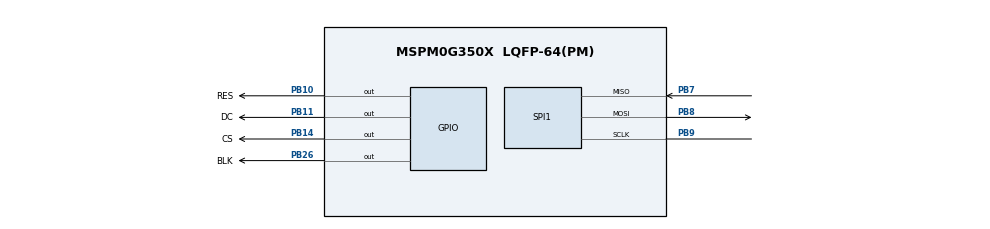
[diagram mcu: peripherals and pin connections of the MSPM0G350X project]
/**
 * @cliArgs --device "MSPM0G350X" --part "Default" --package "LQFP-64(PM)" --product "mspm0_sdk@2.10.00.04"
 * @versions {"tool":"1.26.2+4477"}
 */

/**
 * Import the modules used in this configuration.
 */
const GPIO   = scripting.addModule("/ti/driverlib/GPIO", {}, false);
const GPIO1  = GPIO.addInstance();
const SPI    = scripting.addModule("/ti/driverlib/SPI", {}, false);
const SPI1   = SPI.addInstance();
const SYSCTL = scripting.addModule("/ti/driverlib/SYSCTL");

/**
 * Write custom configuration values to the imported modules.
 */
GPIO1.port                          = "PORTB";
GPIO1.$name                         = "LCD";
GPIO1.associatedPins.create(4);
GPIO1.associatedPins[0].$name       = "RES";
GPIO1.associatedPins[0].ioStructure = "SD";
GPIO1.associatedPins[0].pin.$assign = "PB10";
GPIO1.associatedPins[1].$name       = "DC";
GPIO1.associatedPins[1].ioStructure = "SD";
GPIO1.associatedPins[1].pin.$assign = "PB11";
GPIO1.associatedPins[2].$name       = "CS";
GPIO1.associatedPins[2].ioStructure = "SD";
GPIO1.associatedPins[2].pin.$assign = "PB14";
GPIO1.associatedPins[3].$name       = "BLK";
GPIO1.associatedPins[3].ioStructure = "SD";
GPIO1.associatedPins[3].pin.$assign = "PB26";

const Board = scripting.addModule("/ti/driverlib/Board", {}, false);

SPI1.$name                              = "SPI_LCD";
SPI1.frameFormat                        = "MOTO3";
SPI1.targetBitRate                      = 2000000;
SPI1.sclkPinConfig.$name                = "ti_driverlib_gpio_GPIOPinGeneric0";
SPI1.sclkPinConfig.direction            = scripting.forceWrite("OUTPUT");
SPI1.sclkPinConfig.onlyInternalResistor = scripting.forceWrite(false);
SPI1.sclkPinConfig.passedPeripheralType = scripting.forceWrite("Digital");
SPI1.mosiPinConfig.$name                = "ti_driverlib_gpio_GPIOPinGeneric1";
SPI1.mosiPinConfig.direction            = scripting.forceWrite("OUTPUT");
SPI1.mosiPinConfig.hideOutputInversion  = scripting.forceWrite(false);
SPI1.mosiPinConfig.onlyInternalResistor = scripting.forceWrite(false);
SPI1.mosiPinConfig.passedPeripheralType = scripting.forceWrite("Digital");
SPI1.misoPinConfig.$name                = "ti_driverlib_gpio_GPIOPinGeneric2";
SPI1.misoPinConfig.onlyInternalResistor = scripting.forceWrite(false);
SPI1.misoPinConfig.passedPeripheralType = scripting.forceWrite("Digital");
SPI1.peripheral.$assign                 = "SPI1";
SPI1.peripheral.sclkPin.$assign         = "PB9";
SPI1.peripheral.mosiPin.$assign         = "PB8";
SPI1.peripheral.misoPin.$assign         = "PB7";

SYSCTL.forceDefaultClkConfig = true;

/**
 * Pinmux solution for unlocked pins/peripherals. This ensures that minor changes to the automatic solver in a future
 * version of the tool will not impact the pinmux you originally saw.  These lines can be completely deleted in order to
 * re-solve from scratch.
 */
Board.peripheral.$suggestSolution          = "DEBUGSS";
Board.peripheral.swclkPin.$suggestSolution = "PA20";
Board.peripheral.swdioPin.$suggestSolution = "PA19";
SYSCTL.peripheral.$suggestSolution         = "SYSCTL";
